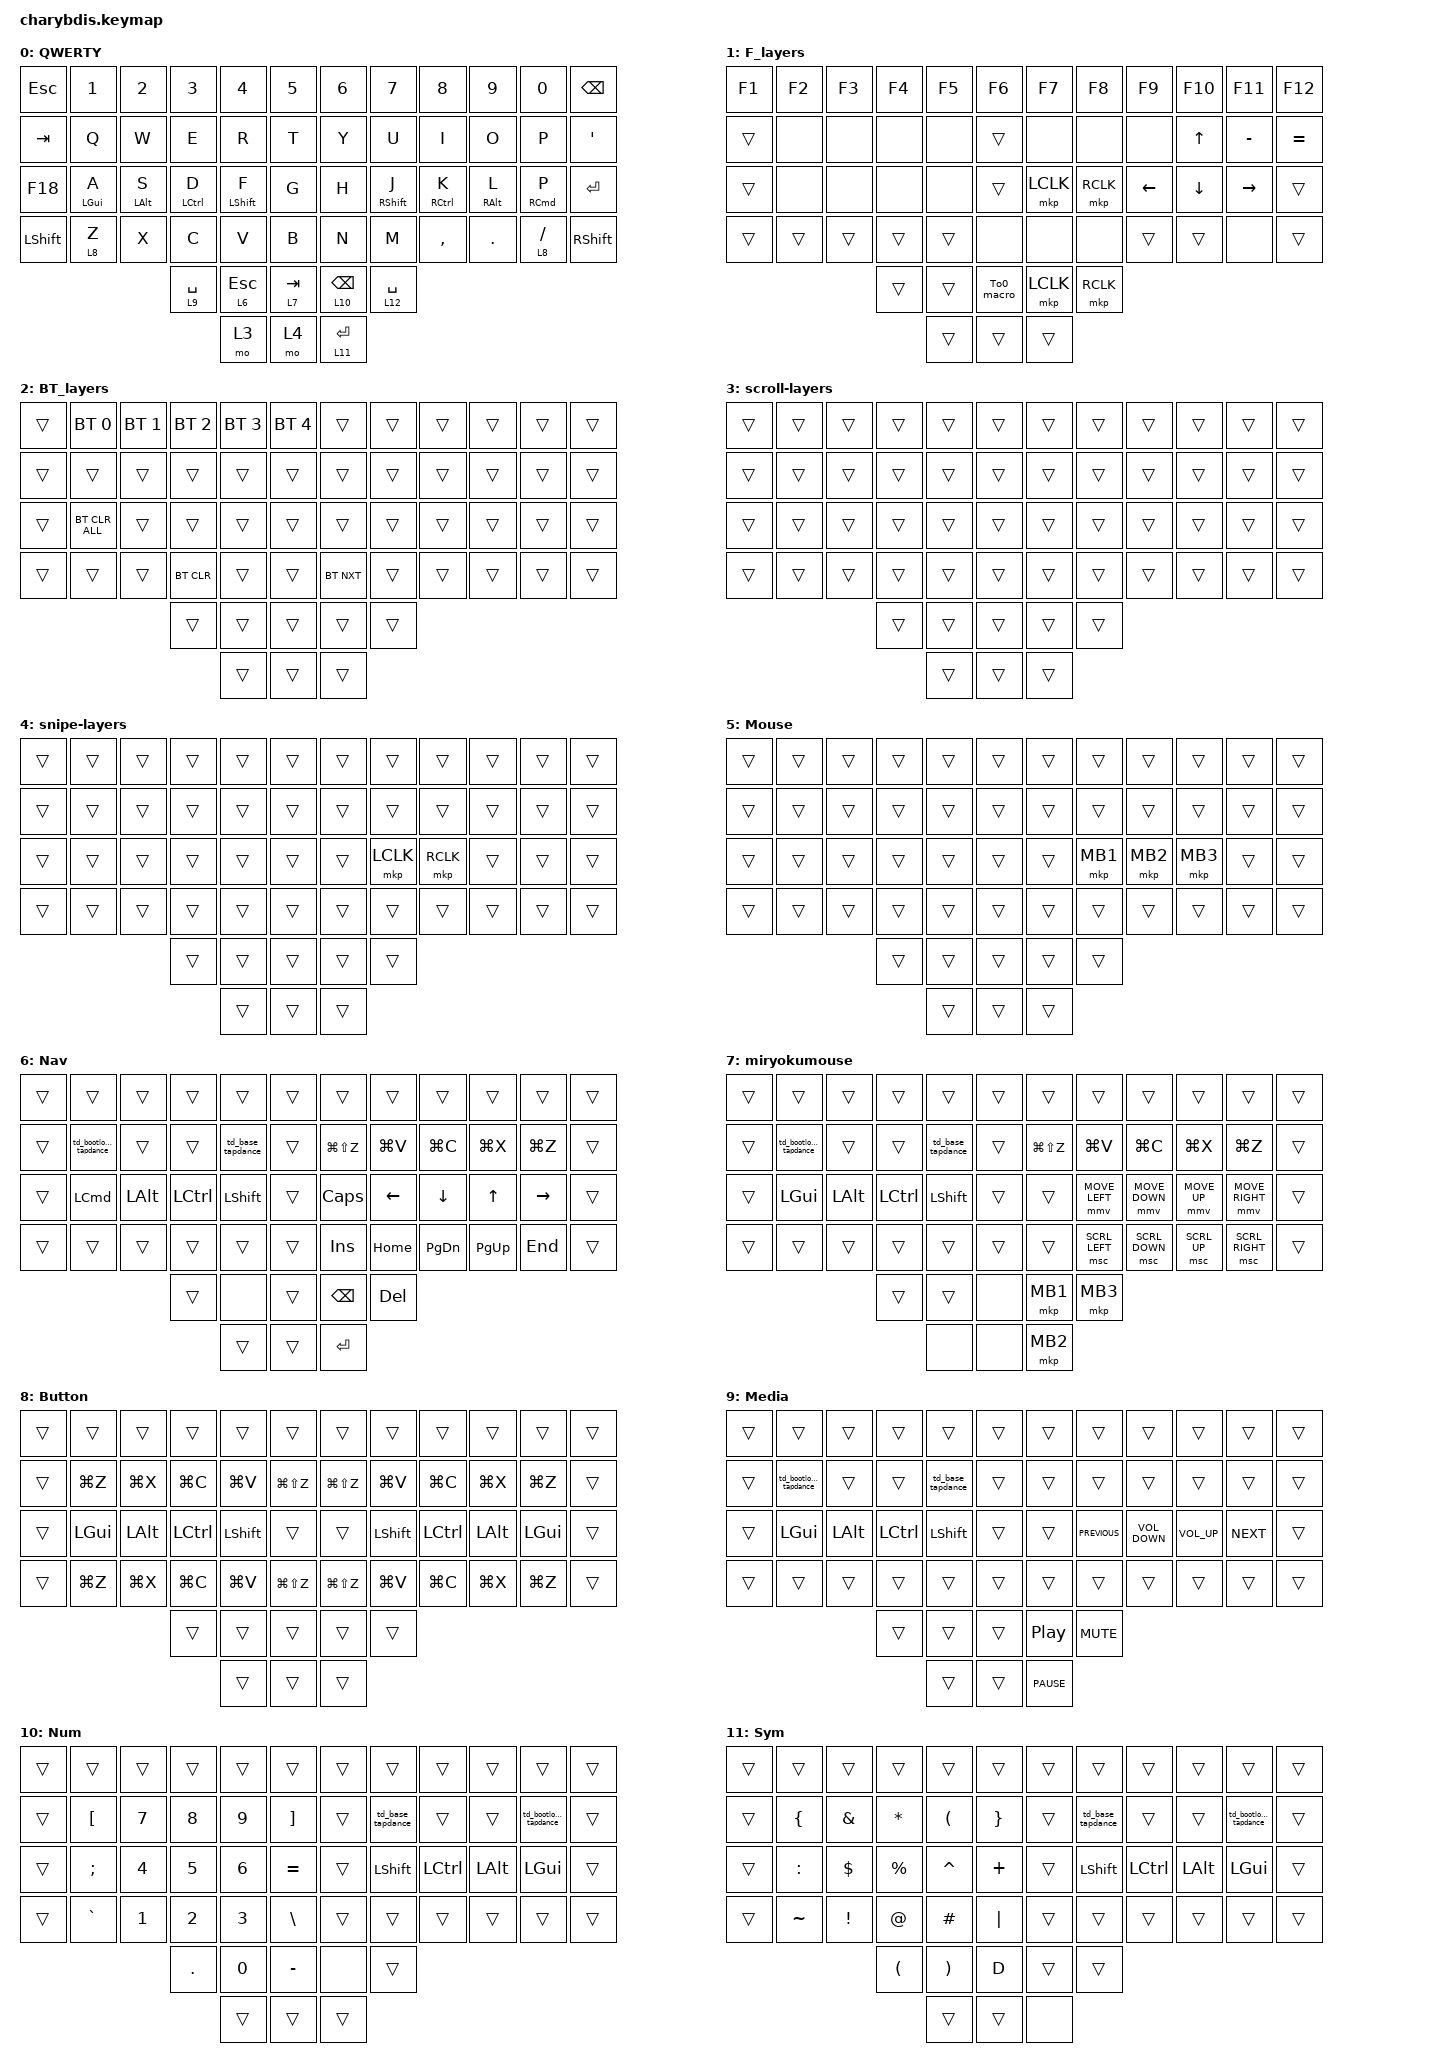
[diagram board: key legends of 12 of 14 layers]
#include <behaviors.dtsi>
#include <dt-bindings/zmk/bt.h>
#include <dt-bindings/zmk/keys.h>
#include <dt-bindings/zmk/pointing.h>
#include <dt-bindings/zmk/rgb.h>

&lt {
    tapping-term-ms = <200>;
    flavor = "balanced";
    quick-tap-ms = <150>;
};

/ {
    macros {
        To1_macro: To1_macro {
            compatible = "zmk,behavior-macro";
            label = "To1_macro";
            #binding-cells = <0>;
            bindings = <&rgb_ug RGB_EFF &rgb_ug RGB_COLOR_HSB(128,100,50) &to 1>;
        };

        To0_macro: To0_macro {
            compatible = "zmk,behavior-macro";
            label = "To0_macro";
            #binding-cells = <0>;
            bindings = <&rgb_ug RGB_EFR &to 0>;
        };

        To2_macro: To2_macro {
            compatible = "zmk,behavior-macro";
            label = "To2_macro";
            #binding-cells = <0>;
            bindings =
                <&to 2>,
                <&macro_wait_time 30>,
                <&rgb_ug RGB_COLOR_HSB(250,100,50)>;
        };
    };

    behaviors {
        hm: homerow-mods {
            compatible = "zmk,behavior-hold-tap";
            label = "HOMEROW-MODS";
            bindings = <&kp>, <&kp>;

            #binding-cells = <2>;
            tapping-term-ms = <200>;
            quick-tap-ms = <130>;
            flavor = "tap-preferred";
            require-prior-idle-ms = <130>;
        };

        td_bootloader_tapdance: td_bootloader_tapdance {
            compatible = "zmk,behavior-tap-dance";
            label = "TD_BOOTLOADER_TAPDANCE";
            #binding-cells = <0>;
            bindings = <&none>, <&bootloader>;

            tapping-term-ms = <350>;
        };

        td_base_tapdance: td_base_tapdance {
            compatible = "zmk,behavior-tap-dance";
            label = "TD_BASE_TAPDANCE";
            #binding-cells = <0>;
            bindings = <&none>, <&to 0>;

            tapping-term-ms = <350>;
        };
    };

    combos {
        compatible = "zmk,combos";

        leftclick {
            bindings = <&mkp LCLK>;
            key-positions = <31 32>;
        };

        rightclick {
            bindings = <&mkp RCLK>;
            key-positions = <32 33>;
        };

        scroll {
            bindings = <&mo 3>;
            key-positions = <31 33>;
        };

        leftscrollup {
            bindings = <&msc SCRL_UP>;
            key-positions = <14 15>;
            timeout-ms = <30>;
            layers = <0>;
        };

        rightscrollup {
            bindings = <&msc SCRL_DOWN>;
            key-positions = <38 39>;
            timeout-ms = <30>;
            layers = <0>;
        };
    };

    keymap {
        compatible = "zmk,keymap";

        QWERTY {
            bindings = <
&kp ESC         &kp N1      &kp N2      &kp N3              &kp N4            &kp N5       &kp N6            &kp N7             &kp N8               &kp N9           &kp N0               &kp BACKSPACE
&kp TAB         &kp Q       &kp W       &kp E               &kp R             &kp T        &kp Y             &kp U              &kp I                &kp O            &kp P                &kp APOS
&kp F18         &hm LGUI A  &hm LALT S  &hm LEFT_CONTROL D  &hm LEFT_SHIFT F  &kp G        &kp H             &hm RIGHT_SHIFT J  &hm RIGHT_CONTROL K  &hm RIGHT_ALT L  &hm RIGHT_COMMAND P  &kp RETURN
&kp LEFT_SHIFT  &lt 8 Z     &kp X       &kp C               &kp V             &kp B        &kp N             &kp M              &kp COMMA            &kp DOT          &lt 8 SLASH          &kp RIGHT_SHIFT
                                        &lt 9 SPACE         &lt 6 ESC         &lt 7 TAB    &lt 10 BACKSPACE  &lt 12 SPACE
                                                            &mo 3             &mo 4        &lt 11 RETURN
            >;
        };

        F_layers {
            bindings = <
&kp F1  &kp F2  &kp F3  &kp F4  &kp F5  &kp F6        &kp F7     &kp F8     &kp F9    &kp F10       &kp F11    &kp F12
&trans  &none   &none   &none   &none   &trans        &none      &none      &none     &kp UP_ARROW  &kp MINUS  &kp EQUAL
&trans  &none   &none   &none   &none   &trans        &mkp LCLK  &mkp RCLK  &kp LEFT  &kp DOWN      &kp RIGHT  &trans
&trans  &trans  &trans  &trans  &trans  &none         &none      &none      &trans    &trans        &none      &trans
                        &trans  &trans  &To0_macro    &mkp LCLK  &mkp RCLK
                                &trans  &trans        &trans
            >;
        };

        BT_layers {
            bindings = <
&trans  &bt BT_SEL 0    &bt BT_SEL 1  &bt BT_SEL 2  &bt BT_SEL 3  &bt BT_SEL 4    &trans      &trans  &trans  &trans  &trans  &trans
&trans  &trans          &trans        &trans        &trans        &trans          &trans      &trans  &trans  &trans  &trans  &trans
&trans  &bt BT_CLR_ALL  &trans        &trans        &trans        &trans          &trans      &trans  &trans  &trans  &trans  &trans
&trans  &trans          &trans        &bt BT_CLR    &trans        &trans          &bt BT_NXT  &trans  &trans  &trans  &trans  &trans
                                      &trans        &trans        &trans          &trans      &trans
                                                    &trans        &trans          &trans
            >;
        };

        scroll-layers {
            bindings = <
&trans  &trans  &trans  &trans  &trans  &trans    &trans  &trans  &trans  &trans  &trans  &trans
&trans  &trans  &trans  &trans  &trans  &trans    &trans  &trans  &trans  &trans  &trans  &trans
&trans  &trans  &trans  &trans  &trans  &trans    &trans  &trans  &trans  &trans  &trans  &trans
&trans  &trans  &trans  &trans  &trans  &trans    &trans  &trans  &trans  &trans  &trans  &trans
                        &trans  &trans  &trans    &trans  &trans
                                &trans  &trans    &trans
            >;
        };

        snipe-layers {
            bindings = <
&trans  &trans  &trans  &trans  &trans  &trans    &trans  &trans     &trans     &trans  &trans  &trans
&trans  &trans  &trans  &trans  &trans  &trans    &trans  &trans     &trans     &trans  &trans  &trans
&trans  &trans  &trans  &trans  &trans  &trans    &trans  &mkp LCLK  &mkp RCLK  &trans  &trans  &trans
&trans  &trans  &trans  &trans  &trans  &trans    &trans  &trans     &trans     &trans  &trans  &trans
                        &trans  &trans  &trans    &trans  &trans
                                &trans  &trans    &trans
            >;
        };

        Mouse {
            bindings = <
&trans  &trans  &trans  &trans  &trans  &trans    &trans  &trans    &trans    &trans    &trans  &trans
&trans  &trans  &trans  &trans  &trans  &trans    &trans  &trans    &trans    &trans    &trans  &trans
&trans  &trans  &trans  &trans  &trans  &trans    &trans  &mkp MB1  &mkp MB2  &mkp MB3  &trans  &trans
&trans  &trans  &trans  &trans  &trans  &trans    &trans  &trans    &trans    &trans    &trans  &trans
                        &trans  &trans  &trans    &trans  &trans
                                &trans  &trans    &trans
            >;
        };

        Nav {
            bindings = <
&trans  &trans                   &trans        &trans            &trans             &trans    &trans         &trans          &trans          &trans        &trans           &trans
&trans  &td_bootloader_tapdance  &trans        &trans            &td_base_tapdance  &trans    &kp LG(LS(Z))  &kp LG(V)       &kp LG(C)       &kp LG(X)     &kp LG(Z)        &trans
&trans  &kp LEFT_COMMAND         &kp LEFT_ALT  &kp LEFT_CONTROL  &kp LEFT_SHIFT     &trans    &kp CAPSLOCK   &kp LEFT_ARROW  &kp DOWN_ARROW  &kp UP_ARROW  &kp RIGHT_ARROW  &trans
&trans  &trans                   &trans        &trans            &trans             &trans    &kp INSERT     &kp HOME        &kp PAGE_DOWN   &kp PAGE_UP   &kp END          &trans
                                               &trans            &none              &trans    &kp BACKSPACE  &kp DELETE
                                                                 &trans             &trans    &kp RET
            >;
        };

        miryokumouse {
            bindings = <
&trans  &trans                   &trans    &trans     &trans             &trans    &trans         &trans          &trans          &trans        &trans           &trans
&trans  &td_bootloader_tapdance  &trans    &trans     &td_base_tapdance  &trans    &kp LG(LS(Z))  &kp LG(V)       &kp LG(C)       &kp LG(X)     &kp LG(Z)        &trans
&trans  &kp LGUI                 &kp LALT  &kp LCTRL  &kp LSHFT          &trans    &trans         &mmv MOVE_LEFT  &mmv MOVE_DOWN  &mmv MOVE_UP  &mmv MOVE_RIGHT  &trans
&trans  &trans                   &trans    &trans     &trans             &trans    &trans         &msc SCRL_LEFT  &msc SCRL_DOWN  &msc SCRL_UP  &msc SCRL_RIGHT  &trans
                                           &trans     &trans             &none     &mkp MB1       &mkp MB3
                                                      &none              &none     &mkp MB2
            >;
        };

        Button {
            bindings = <
&trans  &trans     &trans     &trans     &trans     &trans           &trans         &trans     &trans     &trans     &trans     &trans
&trans  &kp LG(Z)  &kp LG(X)  &kp LG(C)  &kp LG(V)  &kp LG(LS(Z))    &kp LG(LS(Z))  &kp LG(V)  &kp LG(C)  &kp LG(X)  &kp LG(Z)  &trans
&trans  &kp LGUI   &kp LALT   &kp LCTRL  &kp LSHFT  &trans           &trans         &kp LSHFT  &kp LCTRL  &kp LALT   &kp LGUI   &trans
&trans  &kp LG(Z)  &kp LG(X)  &kp LG(C)  &kp LG(V)  &kp LG(LS(Z))    &kp LG(LS(Z))  &kp LG(V)  &kp LG(C)  &kp LG(X)  &kp LG(Z)  &trans
                              &trans     &trans     &trans           &trans         &trans
                                         &trans     &trans           &trans
            >;
        };

        Media {
            bindings = <
&trans  &trans                   &trans    &trans     &trans             &trans    &trans            &trans          &trans             &trans           &trans      &trans
&trans  &td_bootloader_tapdance  &trans    &trans     &td_base_tapdance  &trans    &trans            &trans          &trans             &trans           &trans      &trans
&trans  &kp LGUI                 &kp LALT  &kp LCTRL  &kp LSHFT          &trans    &trans            &kp C_PREVIOUS  &kp C_VOLUME_DOWN  &kp C_VOLUME_UP  &kp C_NEXT  &trans
&trans  &trans                   &trans    &trans     &trans             &trans    &trans            &trans          &trans             &trans           &trans      &trans
                                           &trans     &trans             &trans    &kp C_PLAY_PAUSE  &kp C_MUTE
                                                      &trans             &trans    &kp C_PAUSE
            >;
        };

        Num {
            bindings = <
&trans  &trans     &trans  &trans   &trans  &trans       &trans  &trans             &trans     &trans    &trans                   &trans
&trans  &kp LBKT   &kp N7  &kp N8   &kp N9  &kp RBKT     &trans  &td_base_tapdance  &trans     &trans    &td_bootloader_tapdance  &trans
&trans  &kp SEMI   &kp N4  &kp N5   &kp N6  &kp EQUAL    &trans  &kp LSHFT          &kp LCTRL  &kp LALT  &kp LGUI                 &trans
&trans  &kp GRAVE  &kp N1  &kp N2   &kp N3  &kp BSLH     &trans  &trans             &trans     &trans    &trans                   &trans
                           &kp DOT  &kp N0  &kp MINUS    &none   &trans
                                    &trans  &trans       &trans
            >;
        };

        Sym {
            bindings = <
&trans  &trans          &trans           &trans                &trans                 &trans             &trans  &trans             &trans     &trans    &trans                   &trans
&trans  &kp LEFT_BRACE  &kp AMPERSAND    &kp ASTERISK          &kp LEFT_PARENTHESIS   &kp RIGHT_BRACE    &trans  &td_base_tapdance  &trans     &trans    &td_bootloader_tapdance  &trans
&trans  &kp COLON       &kp DOLLAR       &kp PERCENT           &kp CARET              &kp PLUS           &trans  &kp LSHFT          &kp LCTRL  &kp LALT  &kp LGUI                 &trans
&trans  &kp TILDE       &kp EXCLAMATION  &kp AT_SIGN           &kp HASH               &kp PIPE           &trans  &trans             &trans     &trans    &trans                   &trans
                                         &kp LEFT_PARENTHESIS  &kp RIGHT_PARENTHESIS  &kp D              &trans  &trans
                                                               &trans                 &trans             &none
            >;
        };

        Function {
            bindings = <
&trans  &trans   &trans  &trans       &trans     &trans                  &trans  &trans             &trans     &trans    &trans                   &trans
&trans  &kp F12  &kp F7  &kp F8       &kp F9     &kp LG(LS(NUMBER_5))    &trans  &td_base_tapdance  &trans     &trans    &td_bootloader_tapdance  &trans
&trans  &kp F11  &kp F4  &kp F5       &kp F6     &kp LG(UP_ARROW)        &trans  &kp LSHFT          &kp LCTRL  &kp LALT  &kp LGUI                 &trans
&trans  &kp F10  &kp F1  &kp F2       &kp F3     &kp LG(DOWN)            &trans  &trans             &trans     &trans    &trans                   &trans
                         &kp LG(TAB)  &kp SPACE  &kp TAB                 &trans  &none
                                      &trans     &trans                  &trans
            >;
        };

        AdditionalFeatures {
            bindings = <
&trans  &trans       &trans  &trans  &trans  &trans    &trans  &trans  &trans  &trans  &trans       &trans
&trans  &bootloader  &trans  &trans  &to 0   &trans    &trans  &to 0   &trans  &trans  &bootloader  &trans
&trans  &trans       &trans  &trans  &trans  &trans    &trans  &trans  &trans  &trans  &trans       &trans
&trans  &trans       &trans  &trans  &trans  &trans    &trans  &trans  &trans  &trans  &trans       &trans
                             &trans  &trans  &trans    &trans  &trans
                                     &trans  &trans    &trans
            >;
        };
    };
};
